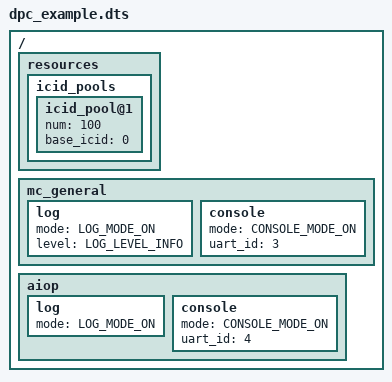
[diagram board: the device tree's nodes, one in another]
/dts-v1/;
/* DPC */
/ {
	resources {
		icid_pools {
			icid_pool@1 {
				num = <100>;
				base_icid = <0>;
			};
		};
	};	
	mc_general {
		log {
			mode = "LOG_MODE_ON";
			level = "LOG_LEVEL_INFO";
		};
		console {
			mode = "CONSOLE_MODE_ON";
			uart_id = <3>;
		};
	};
	aiop {
		log {
			mode = "LOG_MODE_ON";
		};
		console {
			mode = "CONSOLE_MODE_ON";
			uart_id = <4>;
		};
	};
};
